NS_ :

BS_:

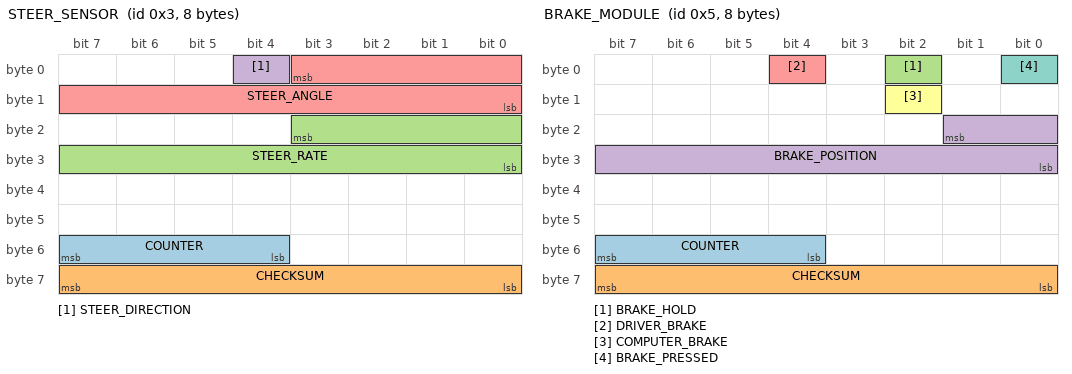
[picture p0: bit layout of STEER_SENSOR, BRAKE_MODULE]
BO_ 3 STEER_SENSOR: 8 XXX
 SG_ COUNTER : 55|4@0+ (1,0) [0|15] "" XXX
 SG_ CHECKSUM : 63|8@0+ (1,0) [0|255] "" XXX
 SG_ STEER_RATE : 19|12@0- (0.5,0) [0|255] "" XXX
 SG_ STEER_DIRECTION : 4|1@0+ (1,2) [0|1] "" XXX
 SG_ STEER_ANGLE : 3|12@0- (-0.5,0) [-500|500] "degrees" XXX

BO_ 5 BRAKE_MODULE: 8 XXX
 SG_ COUNTER : 55|4@0+ (1,0) [0|15] "" XXX
 SG_ CHECKSUM : 63|8@0+ (1,0) [0|255] "" XXX
 SG_ BRAKE_HOLD : 2|1@0+ (1,0) [0|1] "" XXX
 SG_ BRAKE_POSITION : 17|10@0+ (1,0) [0|65535] "" XXX
 SG_ DRIVER_BRAKE : 4|1@0+ (1,0) [0|1] "" XXX
 SG_ COMPUTER_BRAKE : 10|1@0+ (1,0) [0|1] "" XXX
 SG_ BRAKE_PRESSED : 0|1@1+ (1,0) [0|1] "" XXX

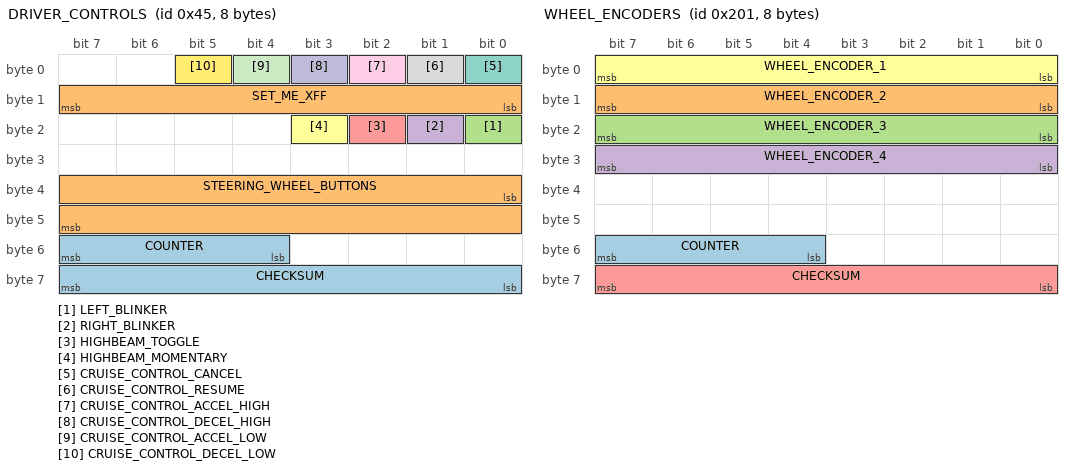
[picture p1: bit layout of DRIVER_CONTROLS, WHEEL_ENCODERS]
BO_ 69 DRIVER_CONTROLS: 8 XXX
 SG_ COUNTER : 55|4@0+ (1,0) [0|15] "" XXX
 SG_ STEERING_WHEEL_BUTTONS : 32|16@1+ (1,0) [0|255] "4 directional, 2 volume control & 2 phone buttons" XXX
 SG_ LEFT_BLINKER : 16|1@0+ (1,0) [0|1] "" XXX
 SG_ RIGHT_BLINKER : 17|1@0+ (1,0) [0|1] "" XXX
 SG_ HIGHBEAM_TOGGLE : 18|1@0+ (1,0) [0|1] "" XXX
 SG_ HIGHBEAM_MOMENTARY : 19|1@0+ (1,0) [0|1] "" XXX
 SG_ CRUISE_CONTROL_CANCEL : 0|1@0+ (1,0) [0|1] "" XXX
 SG_ CRUISE_CONTROL_RESUME : 1|1@0+ (1,0) [0|1] "" XXX
 SG_ CRUISE_CONTROL_ACCEL_HIGH : 2|1@0+ (1,0) [0|1] "" XXX
 SG_ CRUISE_CONTROL_DECEL_HIGH : 3|1@0+ (1,0) [0|1] "" XXX
 SG_ CRUISE_CONTROL_ACCEL_LOW : 4|1@0+ (1,0) [0|1] "" XXX
 SG_ CRUISE_CONTROL_DECEL_LOW : 5|1@0+ (1,0) [0|1] "" XXX
 SG_ CHECKSUM : 63|8@0+ (1,0) [0|255] "" XXX
 SG_ SET_ME_XFF : 15|8@0+ (1,0) [0|255] "" XXX

BO_ 513 WHEEL_ENCODERS: 8 XXX
 SG_ COUNTER : 55|4@0+ (1,0) [0|15] "" XXX
 SG_ WHEEL_ENCODER_2 : 15|8@0+ (1,0) [0|255] "" XXX
 SG_ WHEEL_ENCODER_3 : 23|8@0+ (1,0) [0|255] "" XXX
 SG_ WHEEL_ENCODER_4 : 31|8@0+ (1,0) [0|255] "" XXX
 SG_ CHECKSUM : 56|8@1+ (1,0) [0|255] "" XXX
 SG_ WHEEL_ENCODER_1 : 7|8@0+ (1,0) [0|255] "" XXX

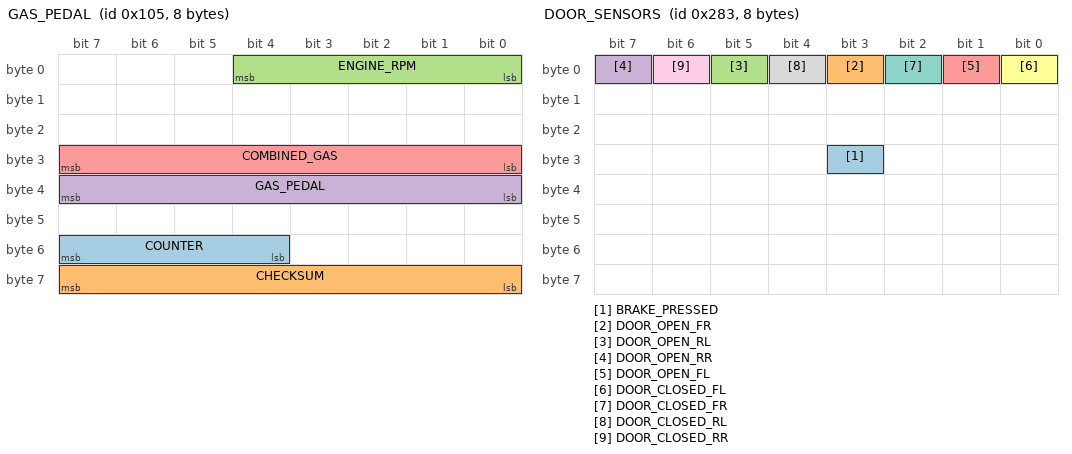
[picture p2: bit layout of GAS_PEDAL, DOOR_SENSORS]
BO_ 261 GAS_PEDAL: 8 XXX
 SG_ COUNTER : 55|4@0+ (1,0) [0|15] "" XXX
 SG_ CHECKSUM : 63|8@0+ (1,0) [0|255] "" XXX
 SG_ ENGINE_RPM : 4|5@0+ (1,0) [0|255] "" XXX
 SG_ GAS_PEDAL : 39|8@0+ (1,0) [0|255] "" XXX
 SG_ COMBINED_GAS : 31|8@0+ (1,0) [0|255] "" XXX

BO_ 643 DOOR_SENSORS: 8 XXX
 SG_ BRAKE_PRESSED : 27|1@0+ (1,0) [0|1] "" XXX
 SG_ DOOR_OPEN_FR : 3|1@1+ (1,0) [0|3] "" XXX
 SG_ DOOR_OPEN_RL : 5|1@0+ (1,0) [0|3] "" XXX
 SG_ DOOR_OPEN_RR : 7|1@0+ (1,0) [0|3] "" XXX
 SG_ DOOR_OPEN_FL : 1|1@0+ (1,0) [0|1] "" XXX
 SG_ DOOR_CLOSED_FL : 0|1@0+ (1,0) [0|1] "" XXX
 SG_ DOOR_CLOSED_FR : 2|1@0+ (1,0) [0|1] "" XXX
 SG_ DOOR_CLOSED_RL : 4|1@0+ (1,0) [0|1] "" XXX
 SG_ DOOR_CLOSED_RR : 6|1@0+ (1,0) [0|1] "" XXX

BO_ 885 SEATBELT_SENSORS: 8 XXX
 SG_ SEATBELT_DRIVER_LATCHED : 16|1@0+ (1,0) [0|1] "" XXX
 SG_ SEATBELT_PASSENGER_LATCHED : 18|1@0+ (1,0) [0|1] "" XXX

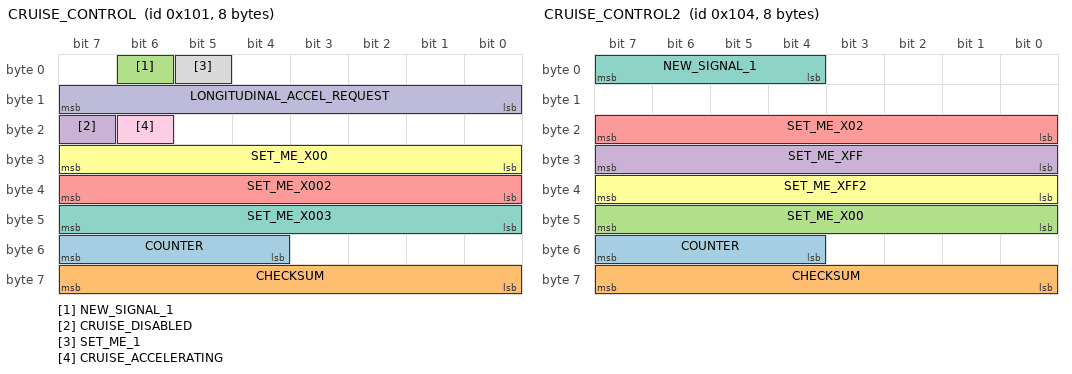
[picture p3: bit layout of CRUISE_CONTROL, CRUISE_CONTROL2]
BO_ 257 CRUISE_CONTROL: 8 XXX
 SG_ COUNTER : 55|4@0+ (1,0) [0|15] "" XXX
 SG_ CHECKSUM : 63|8@0+ (1,0) [0|255] "" XXX
 SG_ NEW_SIGNAL_1 : 6|1@0+ (1,0) [0|255] "" XXX
 SG_ CRUISE_DISABLED : 23|1@0+ (1,0) [0|1] "" XXX
 SG_ SET_ME_X002 : 39|8@0+ (1,0) [0|255] "" XXX
 SG_ SET_ME_X00 : 31|8@0+ (1,0) [0|255] "" XXX
 SG_ SET_ME_X003 : 47|8@0+ (1,0) [0|255] "" XXX
 SG_ SET_ME_1 : 5|1@0+ (1,0) [0|1] "" XXX
 SG_ CRUISE_ACCELERATING : 22|1@0+ (1,0) [0|1] "" XXX
 SG_ LONGITUDINAL_ACCEL_REQUEST : 15|8@0- (1,0) [0|127] "" XXX

BO_ 260 CRUISE_CONTROL2: 8 XXX
 SG_ COUNTER : 55|4@0+ (1,0) [0|15] "" XXX
 SG_ CHECKSUM : 63|8@0+ (1,0) [0|255] "" XXX
 SG_ SET_ME_X00 : 47|8@0+ (1,0) [0|255] "" XXX
 SG_ SET_ME_XFF : 31|8@0+ (1,0) [0|65535] "" XXX
 SG_ SET_ME_X02 : 23|8@0+ (1,0) [0|255] "" XXX
 SG_ SET_ME_XFF2 : 39|8@0+ (1,0) [0|255] "" XXX
 SG_ NEW_SIGNAL_1 : 7|4@0+ (1,0) [0|255] "" XXX

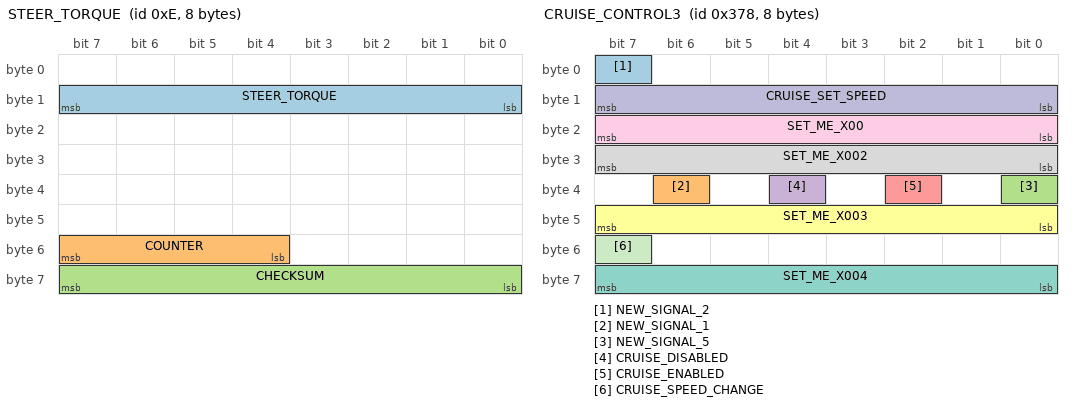
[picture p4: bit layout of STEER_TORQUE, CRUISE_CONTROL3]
BO_ 14 STEER_TORQUE: 8 XXX
 SG_ STEER_TORQUE : 15|8@0+ (1,0) [0|255] "" XXX
 SG_ COUNTER : 55|4@0+ (1,0) [0|15] "" XXX
 SG_ CHECKSUM : 63|8@0+ (1,0) [0|255] "" XXX

BO_ 888 CRUISE_CONTROL3: 8 XXX
 SG_ NEW_SIGNAL_2 : 7|1@0+ (1,0) [0|1] "" XXX
 SG_ NEW_SIGNAL_1 : 38|1@0+ (1,0) [0|1] "" XXX
 SG_ NEW_SIGNAL_5 : 32|1@0+ (1,0) [0|1] "" XXX
 SG_ CRUISE_DISABLED : 36|1@0+ (1,0) [0|1] "" XXX
 SG_ CRUISE_ENABLED : 34|1@0+ (1,0) [0|1] "" XXX
 SG_ SET_ME_X003 : 47|8@0+ (1,0) [0|255] "" XXX
 SG_ SET_ME_X004 : 63|8@0+ (1,0) [0|255] "" XXX
 SG_ SET_ME_X002 : 31|8@0+ (1,0) [0|255] "" XXX
 SG_ SET_ME_X00 : 23|8@0+ (1,0) [0|255] "" XXX
 SG_ CRUISE_SET_SPEED : 15|8@0+ (1,0) [0|63] "mph" XXX
 SG_ CRUISE_SPEED_CHANGE : 55|1@0+ (1,0) [0|1] "" XXX

BO_ 307 POWER_SEATS: 8 XXX
 SG_ DRIVER_FORWARD : 0|1@0+ (1,0) [0|1] "" XXX
 SG_ DRIVER_BACK : 1|1@0+ (1,0) [0|1] "" XXX

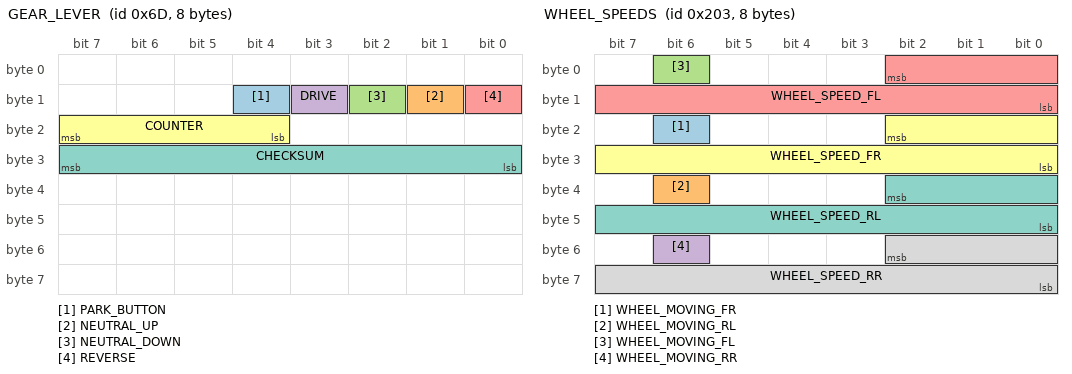
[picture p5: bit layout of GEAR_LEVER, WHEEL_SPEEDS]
BO_ 109 GEAR_LEVER: 8 XXX
 SG_ PARK_BUTTON : 12|1@0+ (1,0) [0|1] "" XXX
 SG_ NEUTRAL_UP : 9|1@0+ (1,0) [0|1] "" XXX
 SG_ NEUTRAL_DOWN : 10|1@0+ (1,0) [0|1] "" XXX
 SG_ DRIVE : 11|1@0+ (1,0) [0|1] "" XXX
 SG_ REVERSE : 8|1@0+ (1,0) [0|1] "" XXX
 SG_ COUNTER : 23|4@0+ (1,0) [0|15] "" XXX
 SG_ CHECKSUM : 31|8@0+ (1,0) [0|255] "" XXX

BO_ 115 GEAR_PACKET: 8 XXX
 SG_ GEAR : 0|4@1+ (1,0) [0|15] "" XXX

BO_ 581 IGNITION: 8 XXX

BO_ 515 WHEEL_SPEEDS: 8 XXX
 SG_ WHEEL_MOVING_FR : 22|1@1+ (1,0) [0|15] "" XXX
 SG_ WHEEL_MOVING_RL : 38|1@0+ (1,0) [0|1] "" XXX
 SG_ WHEEL_MOVING_FL : 6|1@0+ (1,0) [0|1] "" XXX
 SG_ WHEEL_MOVING_RR : 54|1@0+ (1,0) [0|1] "" XXX
 SG_ WHEEL_SPEED_FL : 2|11@0+ (0.0375,0) [0|255] "mph" XXX
 SG_ WHEEL_SPEED_FR : 18|11@0+ (0.0375,0) [0|255] "mph" XXX
 SG_ WHEEL_SPEED_RL : 34|11@0+ (0.0375,0) [0|255] "mph" XXX
 SG_ WHEEL_SPEED_RR : 50|11@0+ (0.0375,0) [0|255] "mph" XXX

BU_: RRSRR_FO LRSRR_FO CIPM_FO _DOFIMU2_FO _DOFIMU1_FO DMS_FO AMM_FO EOCM2B_IMX6_FO EOCM2B_K2_FO EOCM2B_K1_FO EOCM2A_IMX6_FO EOCM2A_K2_FO EOCM2A_K1_FO NVS_FO Dummy_FO TestTool_FO LRR_FO RFSRR_FO LFSRR_FO RSRR_FO VIS_FO EOCM_F_FO VIS2_FO
VAL_TABLE_ vt_BooleanValues 1 "true" 0 "false" ;
VAL_TABLE_ FrntVsnInPthVehBrkNwSt 10 "Active" 5 "Inactive" ;
VAL_TABLE_ FrntVsnClostPedBrkNwSt 10 "Active" 5 "Inactive" ;
VAL_TABLE_ DrvrMonSysEngSt 7 "Unused and Reserved 1" 6 "Recovering" 5 "Tracking" 4 "Searching" 3 "Video test port only" 2 "Idle" 1 "Invalid state" 0 "Does not exist or DME" ;
VAL_TABLE_ DrvrMonEngUnrecvrFltCod 7 "Unused and Reserved 3" 6 "Unused and Reserved 2" 5 "Unused and Reserved 1" 4 "Vehicle power supply Errors" 3 "Problem with LED illuminators" 2 "Vehicle input signals Errors" 1 "Problem with imager" 0 "Ok" ;
VAL_TABLE_ DrvrMonEngRecvrFltCod 3 "Engine is unable to find a face" 2 "Input Images too dark" 1 "Input images too bright" 0 "Ok" ;
VAL_TABLE_ DrvrMntrSysVTP 1 "Video test port active" 0 "Video test port inactive" ;
VAL_TABLE_ DrvrAttnStatCnfdc 3 "High" 2 "Medium" 1 "Low" 0 "Lowest" ;
VAL_TABLE_ DrvrAttnStat 7 "Invalid" 6 "Driver is exhibiting sleep" 5 "Driver is exhibiting microsleep" 4 "Attention is Center Console" 3 "Attention is Drivers Lap" 2 "Attention is Off Road" 1 "Attention is On Road" 0 "Unknown" ;
VAL_TABLE_ PPSMd 7 "GNSS and RTX and DR and MM" 6 "DR ONLY" 5 "GNSS and RTX and DR" 4 "GNSS and SBAS and DR" 3 "GNSS and DR" 2 "GNSS and  RTX" 1 "GNSS and SBAS" 0 "GNSS Standalone" ;
VAL_TABLE_ AdvDrvAstMpPrfShrtAcur 3 "Accuracy Is Unknown" 2 "Lowest Accuracy" 1 "Medium Accuracy" 0 "Highest Accuracy" ;
VAL_TABLE_ AdvDrAstMpStbRtOfWay 3 "Not Applicable" 2 "Unknown" 1 "Sub Path Has Right Of Way Over Path" 0 "Path Has Right Of Way Over Sub Path" ;
VAL_TABLE_ AdvDrAstMpStbPrtCalRut 3 "Not Applicable" 2 "Unknown" 1 "Path From This Point On Is Part Of Calculated Route" 0 "Path From This Point On Is Not Part Of Calculated Route" ;
VAL_TABLE_ AdvDrAstMpStbMsgTyp 7 "Unused and Reserved 2" 6 "Metadata" 5 "Profile Long" 4 "Profile Short" 3 "Stub" 2 "Segment" 1 "Position" 0 "Unused and Reserved 1" ;
VAL_TABLE_ AdvDrAstMpStbFmOfWay 15 "Not Applicable" 14 "Pedestrian Zone" 13 "Entrance To Or Exit To Service" 12 "Entrance To Or Exit Of A Car Park" 11 "Service Road Or Frontage Road" 10 "Slip Road per Ramp" 9 "Slip Road per Ramp On A Freeway Or Controlled Access Road" 8 "Parallel Road" 7 "Unused and Reserved 2" 6 "Unused and Reserved 1" 5 "Traffic Square per Special Traffic Figure" 4 "Roundabout Circle" 3 "Single Carriageway" 2 "Multiple Carriageway Or Multiply Digitized Road" 1 "Freeway Or Controlled Access Road That Is Not A Slip Road Or Ramp" 0 "Unknown" ;
VAL_TABLE_ AdvDrAstMpStbCmplxInsct 3 "Not Applicable" 2 "Unknown" 1 "Stub Is Part Of Complex Intersection" 0 "Stub Is Not Part Of Complex Intersection" ;
VAL_TABLE_ AdvDrAstMpSegTunl 3 "Not Applicable" 2 "Unknown" 1 "Segment Is Part Of Tunnel" 0 "Segment Is Not A Part Of Tunnel" ;
VAL_TABLE_ AdvDrAstMpSegPrtCalRut 3 "Not Applicable" 2 "Unknown" 1 "Segment Is Part Of Calculated Route" 0 "Segment Is Not Part Of Calculated Route" ;
VAL_TABLE_ AdvDrAstMpSegMsgTyp 7 "Unused and Reserved 2" 6 "Metadata" 5 "Profile Long" 4 "Profile Short" 3 "Stub" 2 "Segment" 1 "Position" 0 "Unused and Reserved 1" ;
VAL_TABLE_ AdvDrAstMpSegFrmOfWay 15 "Not Applicable" 14 "Pedestrian Zone" 13 "Entrance To Or Exit To Service" 12 "Entrance To Or Exit Of A Car Park" 11 "Service Road Or Frontage Road" 10 "Slip Road per Ramp" 9 "Slip Road per Ramp On A Freeway Or Controlled Access Road" 8 "Parallel Road" 7 "Unused and Reserved 2" 6 "Unused and Reserved 1" 5 "Traffic Square per Special Traffic Figure" 4 "Roundabout Circle" 3 "Single Carriageway" 2 "Multiple Carriageway Or Multiply Digitized Road" 1 "Freeway Or Controlled Access Road That Is Not A Slip Road or Ramp" 0 "Unknown" ;
VAL_TABLE_ AdvDrAstMpSegEffSdLmtTp 7 "Not Applicable" 6 "Explicit Snow" 5 "Explicit Rain" 4 "Explicit Time Of Day" 3 "Explicit By Day" 2 "Explicit By Night" 1 "Explicit On Traffic Sign" 0 "Implicit" ;
VAL_TABLE_ AdvDrAstMpSegDivdRd 3 "Not Applicable" 2 "Unknown" 1 "Segment Is Part Of Divided Road" 0 "Segment Is Not Part Of Divided Road" ;
VAL_TABLE_ AdvDrAstMpSegCmplxInsct 3 "Not Applicable" 2 "Unknown" 1 "Segment Is Part Of Complex Intersection" 0 "Segment Is Not Part Of Complex Intersection" ;
VAL_TABLE_ AdvDrAstMpSegBrdg 3 "Not Applicable" 2 "Unknown" 1 "Segment Is Part Of Bridge" 0 "Segment Not Part Of Bridge" ;
VAL_TABLE_ AdvDrAstMpSegBldUpAra 3 "Not Applicable" 2 "Unknown" 1 "Segment Is Part Of Built Up Area" 0 "Segment Is Not Part Of Built Up Area" ;
VAL_TABLE_ AdvDrAstMpMtdtSpdUnt 1 "Miles Per Hour" 0 "Kilometers Per Hour" ;
VAL_TABLE_ AdvDrAstMpMtdtDrvSd 1 "Driving Side Right" 0 "Driving Side Left" ;
VAL_TABLE_ WSMR_WiFiAssnReq 3 "Unexpected Undefined Connection Behavior" 2 "Wi Fi association failed with available credentials" 1 "Failed to receive Wi Fi credentials after 255 attempts" 0 "SSID and Passphrase Request" ;
VAL_TABLE_ StrgColCommsFlt 2 "Disabled Communications DTC" 1 "No Communications Fault" 0 "Communications Fault" ;
VAL_TABLE_ CPMAPINFO4 1 "Hardware Or Software Error" 0 "No Hardware Or Software Error" ;
VAL_TABLE_ AdvDrvAstMpPrfShrt2Acur 3 "Accuracy Is Unknown" 2 "Lowest Accuracy" 1 "Medium Accuracy" 0 "Highest Accuracy" ;
VAL_TABLE_ InterLghtStat 1 "Interior Lights On" 0 "Interior Light Off" ;
VAL_TABLE_ VehLnStatConf 2 "High Confidence" 1 "Low Confidence" 0 "No Confidence" 3 "Very High Confidence" ;
VAL_TABLE_ VehLnStat 3 "Lane Change To Right" 2 "Lane Change To Left" 1 "Staying in Lane" 0 "Unknown" ;
VAL_TABLE_ HrznPrvdRstRq 1 "Reset Not Required" 0 "Reset Required" ;
VAL_TABLE_ ExptNxtTrnstnDirConf 3 "Very High Confidence" 2 "High Confidence" 1 "Low Confidence" 0 "No Confidence" ;
VAL_TABLE_ ExptNxtTrnstnDir 7 "Reserved4" 6 "Reserved3" 5 "Reserved2" 4 "Reserved1" 3 "Traversing Middle Transition" 2 "Traversing Next Transition Right" 1 "Traversing Next Transition Left" 0 "Unknown" ;
VAL_TABLE_ ADASISMsgTypRetrans 7 "GM System Specific" 6 "Meta Data" 5 "Profile Long" 4 "Profile Short" 3 "Stub" 2 "Segment" 1 "Position" 0 "Checksum" ;
VAL_TABLE_ NVSysStat 7 "Needs Headlights" 6 "Temporarily Unavailable" 5 "Not Dark" 4 "Needs Service" 3 "Active" 2 "Inactive" 1 "Initializing" 0 "Unknown" ;
VAL_TABLE_ NVSysPedWrnIndReq 3 "Unused & Reserved" 2 "Pedestrian Alert" 1 "Pedestrian Detected" 0 "None" ;
VAL_TABLE_ NVSysPedDetCstReq 2 "On" 1 "Off" 0 "No Value" ;
VAL_TABLE_ NVSysPedDetCsCrStVal 2 "On" 1 "Off" 0 "No Value" ;
VAL_TABLE_ FwVsnCinCoutPotT9Rev 2 "Right" 1 "Left" 0 "None" ;
VAL_TABLE_ FwVsnCinCoutPotT8Rev 2 "Right" 1 "Left" 0 "None" ;
VAL_TABLE_ FwVsnCinCoutPotT7Rev 2 "Right" 1 "Left" 0 "None" ;
VAL_TABLE_ FwVsnCinCoutPotT6Rev 2 "Right" 1 "Left" 0 "None" ;
VAL_TABLE_ FwVsnCinCoutPotT5Rev 2 "Right" 1 "Left" 0 "None" ;
VAL_TABLE_ FwVsnCinCoutPotT4Rev 2 "Right" 1 "Left" 0 "None" ;
VAL_TABLE_ FwVsnCinCoutPotT3Rev 2 "Right" 1 "Left" 0 "None" ;
VAL_TABLE_ FwVsnCinCoutPotT2Rev 2 "Right" 1 "Left" 0 "None" ;
VAL_TABLE_ FwVsnCinCoutPotT1Rev 2 "Right" 1 "Left" 0 "None" ;
VAL_TABLE_ FwVsnCinCoutPotT12Rev 2 "Right" 1 "Left" 0 "None" ;
VAL_TABLE_ FwVsnCinCoutPotT11Rev 2 "Right" 1 "Left" 0 "None" ;
VAL_TABLE_ FwVsnCinCoutPotT10Rev 2 "Right" 1 "Left" 0 "None" ;
VAL_TABLE_ GFHBObjDirTrk8 1 "Ahead Traffic" 0 "Incoming Traffic" ;
VAL_TABLE_ GFHBObjDirTrk7 1 "Ahead Traffic" 0 "Incoming Traffic" ;
VAL_TABLE_ GFHBObjDirTrk6 1 "Ahead Traffic" 0 "Incoming Traffic" ;
VAL_TABLE_ GFHBObjDirTrk5 1 "Ahead Traffic" 0 "Incoming Traffic" ;
VAL_TABLE_ GFHBObjDirTrk4 1 "Ahead Traffic" 0 "Incoming Traffic" ;
VAL_TABLE_ GFHBObjDirTrk3 1 "Ahead Traffic" 0 "Incoming Traffic" ;
VAL_TABLE_ GFHBObjDirTrk2 1 "Ahead Traffic" 0 "Incoming Traffic" ;
VAL_TABLE_ GFHBObjDirTrk1 1 "Ahead Traffic" 0 "Incoming Traffic" ;
VAL_TABLE_ GFHBFwVsnRelLaneTrk8 3 "Left Lane" 2 "Right Lane" 1 "Host Lane" 0 "Unknown" ;
VAL_TABLE_ GFHBFwVsnRelLaneTrk7 3 "Left Lane" 2 "Right Lane" 1 "Host Lane" 0 "Unknown" ;
VAL_TABLE_ GFHBFwVsnRelLaneTrk6 3 "Left Lane" 2 "Right Lane" 1 "Host Lane" 0 "Unknown" ;
VAL_TABLE_ GFHBFwVsnRelLaneTrk5 3 "Left Lane" 2 "Right Lane" 1 "Host Lane" 0 "Unknown" ;
VAL_TABLE_ GFHBFwVsnRelLaneTrk4 3 "Left Lane" 2 "Right Lane" 1 "Host Lane" 0 "Unknown" ;
VAL_TABLE_ GFHBFwVsnRelLaneTrk3 3 "Left Lane" 2 "Right Lane" 1 "Host Lane" 0 "Unknown" ;
VAL_TABLE_ GFHBFwVsnRelLaneTrk2 3 "Left Lane" 2 "Right Lane" 1 "Host Lane" 0 "Unknown" ;
VAL_TABLE_ GFHBFwVsnRelLaneTrk1 3 "Left Lane" 2 "Right Lane" 1 "Host Lane" 0 "Unknown" ;
VAL_TABLE_ GFHBFwVsnMesStatTrk8 3 "Measured this cycle" 2 "Latent track not detected this cycle" 1 "New Object" 0 "No Object" ;
VAL_TABLE_ GFHBFwVsnMesStatTrk7 3 "Measured this cycle" 2 "Latent track not detected this cycle" 1 "New Object" 0 "No Object" ;
VAL_TABLE_ GFHBFwVsnMesStatTrk6 3 "Measured this cycle" 2 "Latent track not detected this cycle" 1 "New Object" 0 "No Object" ;
VAL_TABLE_ GFHBFwVsnMesStatTrk5 3 "Measured this cycle" 2 "Latent track not detected this cycle" 1 "New Object" 0 "No Object" ;
VAL_TABLE_ GFHBFwVsnMesStatTrk4 3 "Measured this cycle" 2 "Latent track not detected this cycle" 1 "New Object" 0 "No Object" ;
VAL_TABLE_ GFHBFwVsnMesStatTrk3 3 "Measured this cycle" 2 "Latent track not detected this cycle" 1 "New Object" 0 "No Object" ;
VAL_TABLE_ GFHBFwVsnMesStatTrk2 3 "Measured this cycle" 2 "Latent track not detected this cycle" 1 "New Object" 0 "No Object" ;
VAL_TABLE_ GFHBFwVsnMesStatTrk1 3 "Measured this cycle" 2 "Latent track not detected this cycle" 1 "New Object" 0 "No Object" ;
VAL_TABLE_ GFHBFwVsnCnfdncTrk8 3 "Confident" 2 "Speculative" 1 "Highly Speculative" 0 "Invalid" ;
VAL_TABLE_ GFHBFwVsnCnfdncTrk7 3 "Confident" 2 "Speculative" 1 "Highly Speculative" 0 "Invalid" ;
VAL_TABLE_ GFHBFwVsnCnfdncTrk6 3 "Confident" 2 "Speculative" 1 "Highly Speculative" 0 "Invalid" ;
VAL_TABLE_ GFHBFwVsnCnfdncTrk5 3 "Confident" 2 "Speculative" 1 "Highly Speculative" 0 "Invalid" ;
VAL_TABLE_ GFHBFwVsnCnfdncTrk4 3 "Confident" 2 "Speculative" 1 "Highly Speculative" 0 "Invalid" ;
VAL_TABLE_ GFHBFwVsnCnfdncTrk3 3 "Confident" 2 "Speculative" 1 "Highly Speculative" 0 "Invalid" ;
VAL_TABLE_ GFHBFwVsnCnfdncTrk2 3 "Confident" 2 "Speculative" 1 "Highly Speculative" 0 "Invalid" ;
VAL_TABLE_ GFHBFwVsnCnfdncTrk1 0 "Invalid" 3 "Confident" 2 "Speculative" 1 "Highly Speculative" ;
VAL_TABLE_ GFHBFVsnObjTypTrkRev8 12 "Cluster Object" 11 "Child Close to Danger Zone" 10 "Pedestrian Moving Out of Danger Zone" 9 "Pedestrian Moving Into Danger Zone" 8 "Pedestrian Standing Outside Danger Zone" 7 "No Object Present" 6 "Fixed Roadside Object" 5 "Fixed Overhead Object" 4 "Pedestrian" 3 "Motorcycle/ Bicycle" 2 "Large Vehicle (Semi)" 1 "4 Wheel Vehicle (Car)" 0 "Unknown" ;
VAL_TABLE_ GFHBFVsnObjTypTrkRev7 12 "Cluster Object" 11 "Child Close to Danger Zone" 10 "Pedestrian Moving Out of Danger Zone" 9 "Pedestrian Moving Into Danger Zone" 8 "Pedestrian Standing Outside Danger Zone" 7 "No Object Present" 6 "Fixed Roadside Object" 5 "Fixed Overhead Object" 4 "Pedestrian" 3 "Motorcycle/ Bicycle" 2 "Large Vehicle (Semi)" 1 "4 Wheel Vehicle (Car)" 0 "Unknown" ;
VAL_TABLE_ GFHBFVsnObjTypTrkRev6 12 "Cluster Object" 11 "Child Close to Danger Zone" 10 "Pedestrian Moving Out of Danger Zone" 9 "Pedestrian Moving Into Danger Zone" 8 "Pedestrian Standing Outside Danger Zone" 7 "No Object Present" 6 "Fixed Roadside Object" 5 "Fixed Overhead Object" 4 "Pedestrian" 3 "Motorcycle/ Bicycle" 2 "Large Vehicle (Semi)" 1 "4 Wheel Vehicle (Car)" 0 "Unknown" ;
VAL_TABLE_ GFHBFVsnObjTypTrkRev5 12 "Cluster Object" 11 "Child Close to Danger Zone" 10 "Pedestrian Moving Out of Danger Zone" 9 "Pedestrian Moving Into Danger Zone" 8 "Pedestrian Standing Outside Danger Zone" 7 "No Object Present" 6 "Fixed Roadside Object" 5 "Fixed Overhead Object" 4 "Pedestrian" 3 "Motorcycle/ Bicycle" 2 "Large Vehicle (Semi)" 1 "4 Wheel Vehicle (Car)" 0 "Unknown" ;
VAL_TABLE_ GFHBFVsnObjTypTrkRev4 12 "Cluster Object" 11 "Child Close to Danger Zone" 10 "Pedestrian Moving Out of Danger Zone" 9 "Pedestrian Moving Into Danger Zone" 8 "Pedestrian Standing Outside Danger Zone" 7 "No Object Present" 6 "Fixed Roadside Object" 5 "Fixed Overhead Object" 4 "Pedestrian" 3 "Motorcycle/ Bicycle" 2 "Large Vehicle (Semi)" 1 "4 Wheel Vehicle (Car)" 0 "Unknown" ;
VAL_TABLE_ GFHBFVsnObjTypTrkRev3 12 "Cluster Object" 11 "Child Close to Danger Zone" 10 "Pedestrian Moving Out of Danger Zone" 9 "Pedestrian Moving Into Danger Zone" 8 "Pedestrian Standing Outside Danger Zone" 7 "No Object Present" 6 "Fixed Roadside Object" 5 "Fixed Overhead Object" 4 "Pedestrian" 3 "Motorcycle/ Bicycle" 2 "Large Vehicle (Semi)" 1 "4 Wheel Vehicle (Car)" 0 "Unknown" ;
VAL_TABLE_ GFHBFVsnObjTypTrkRev2 12 "Cluster Object" 11 "Child Close to Danger Zone" 10 "Pedestrian Moving Out of Danger Zone" 9 "Pedestrian Moving Into Danger Zone" 8 "Pedestrian Standing Outside Danger Zone" 7 "No Object Present" 6 "Fixed Roadside Object" 5 "Fixed Overhead Object" 4 "Pedestrian" 3 "Motorcycle/ Bicycle" 2 "Large Vehicle (Semi)" 1 "4 Wheel Vehicle (Car)" 0 "Unknown" ;
VAL_TABLE_ GFHBFVsnObjTypTrkRev1 12 "Cluster Object" 11 "Child Close to Danger Zone" 10 "Pedestrian Moving Out of Danger Zone" 9 "Pedestrian Moving Into Danger Zone" 8 "Pedestrian Standing Outside Danger Zone" 7 "No Object Present" 6 "Fixed Roadside Object" 5 "Fixed Overhead Object" 4 "Pedestrian" 3 "Motorcycle/ Bicycle" 2 "Large Vehicle (Semi)" 1 "4 Wheel Vehicle (Car" 0 "Unknown" ;
VAL_TABLE_ CRL_Cnfdnc 7 "Reserved4" 6 "Reserved3" 5 "Reserved2" 4 "Reserved1" 3 "Best" 2 "Marking Present" 1 "Weak Marking" 0 "No Lane" ;
VAL_TABLE_ CLL_Cnfdnc 7 "Reserved4" 6 "Reserved3" 5 "Reserved2" 4 "Reserved1" 3 "Best" 2 "Marking Present" 1 "Weak Marking" 0 "No Lane" ;
VAL_TABLE_ VBBrkCtrlSt 4 "Release Control" 3 "Hold Vehicle" 2 "Apply Brake" 1 "Decrease Torque" 0 "No Action" ;
VAL_TABLE_ ObstacleType 6 "NO_OBJECT" 5 "OBJ_GUARDRAIL" 4 "OBJ_TUNNEL " 3 "OBJ_TRAFFIC_SIGN" 2 "OBJ_VEHICLE" 1 "OBJ_BRIDGE " 0 "OBJ_UNKNOWN" ;
VAL_TABLE_ VpathMode 2 "Mid Hi Speed" 1 "Low Speed" 0 "Disabled" ;
VAL_TABLE_ LaneChngStatus 2 "Lane Change Right" 1 "Lane Change Left" 0 "Idle" ;
VAL_TABLE_ TravelDirection 3 "Other (excessive side slip)" 2 "reverse / stopped in rvrs gear" 1 "Forward / stopped in frwd gear" 0 "Unknown" ;
VAL_TABLE_ TrueOrFalse 1 "true" 0 "false" ;
VAL_TABLE_ ModeCommand 5 "Sensing with Reduced Power" 4 "Undefined" 3 "Radio Silent" 2 "Sensing" 1 "Not Sensing" 0 "Undefined" ;
VAL_TABLE_ LaneSnsLLnPosValid 1 "Invalid" 0 "Valid" ;
VAL_TABLE_ LnSnsRLnPosValid 1 "Invalid" 0 "Valid" ;
VAL_TABLE_ Elevation 3 "Low " 2 "mid (reserved)" 1 "high " 0 "Unknown" ;
VAL_TABLE_ ModeCommandFdbk 5 "Sensing with reduced power" 4 "Undefined" 3 "Radio Silent" 2 "Sensing" 1 "Not Sensing" 0 "Undefined" ;
VAL_TABLE_ relativeLane 3 "Left Lane" 2 "Right Lane" 1 "Host Lane" 0 "Unknown" ;
VAL_TABLE_ RoadTypeInfo 5 "Constiction Zone Exit" 4 "Construction Zone Entry" 3 "Highway" 2 "Secondary Road" 1 "City" 0 "Unknown" ;
VAL_TABLE_ ObjectLossInfo 2 "elevation conditions" 1 "tight curve" 0 "not lost" ;
VAL_TABLE_ MeasurementStatus 3 "Measured this cycle" 2 "Latent track not detctd this cyc" 1 "New Object" 0 "No Object" ;
VAL_TABLE_ ObjectType 7 "no object present" 6 "fixed roadside object" 5 "fixed overhead object" 4 "pedestrian" 3 "motocycle  / bicycle" 2 "Large vehicle (semi)" 1 "4 Wheel Vehicle (car, small trk)" 0 "Unknown" ;
VAL_TABLE_ Confidence 3 "confident" 2 "speculative" 1 "highly speculative" 0 "invalid" ;
VAL_TABLE_ DynamicProp 4 "Moving in opposite direction" 3 "Moving in same direction as host" 2 "Has moved but currently stopped" 1 "Has never moved" 0 "Unknown" ;
VAL_TABLE_ DrvWndPosSt 6 "Fully Opened" 5 "Open More Than C" 4 "Position C" 3 "Position B" 2 "Position A" 1 "Open Less Than A" 0 "Fully Closed" ;
VAL_TABLE_ VehMovSta 4 "Invalid" 3 "Reverse" 2 "Forward" 1 "Neutral" 0 "Parked" ;
VAL_TABLE_ OtsdAmbtLtLvlStat 2 "Day" 1 "Night" 0 "Unknown" ;
VAL_TABLE_ RtTrnLmpAtv 2 "On with telltale" 1 "On without telltale" 0 "Off" ;
VAL_TABLE_ LftTrnLmpAtv 2 "On with telltale" 1 "On without telltale" 0 "Off" ;
VAL_TABLE_ HdlmpBmSelectStat 2 "High Beams" 1 "Low Beams" 0 "Unknown" ;
VAL_TABLE_ DTCI_DTCFaultType 3 "Type C" 2 "Type B" 1 "Type A" 0 "Not Supported" ;
VAL_TABLE_ TrnsShftLvrPos 13 "Forward Range J" 12 "Forward Range I" 15 "Lever Position Unknown" 11 "Forward Range H" 10 "Forward Range G" 9 "Forward Range F" 8 "Forward Range E" 7 "Forward Range D" 6 "Forward Range C" 5 "Forward Range B" 4 "Forward Range A" 3 "Neutral Range" 2 "Reverse Range" 1 "Park Range" 0 "Between Ranges" ;
VAL_TABLE_ SysPwrMd 3 "Crank Request" 2 "Run" 1 "Accessory" 0 "Off" ;
VAL_TABLE_ ValidityStates 1 "Invalid" 0 "Valid" ;

CM_ SG_ 1104 DRIVER_SEAT_BELT_ONOFF "0 - on , 1 = off";
CM_ SG_ 1056 DOOR_RL_STATUS "04 - RL - open";
CM_ SG_ 1056 DOOR_FL_STATUS "28 - FL open , 38 - FR";
CM_ SG_ 1056 RIGHT_SIGNAL_STATUS "R,L shows at same time means hazard";
CM_ SG_ 832 TRANS_MODE "AT - 85 / MT - 8D";
CM_ SG_ 832 TRANS_GEAR_POS "R-7 , 0 - N";
CM_ SG_ 821 CRUSE_ONOFF "Cruse Switch";
CM_ SG_ 821 CRUSE_ENABLED "Cruse enabled";
CM_ SG_ 821 THROTTLE_PEDAL_POS "Real Pedal Pos";
CM_ SG_ 821 THROTTLE_POS "Throttle Pos for Cruse Mode";
CM_ SG_ 906 ABS_UNDEF1 "ABS force";
CM_ SG_ 906 SPEED_FL "used for car speed in dash board";
VAL_ 481 DistanceButton 1 "Active" 0 "Inactive" ;
VAL_ 481 LKAButton 1 "Active" 0 "Inactive" ;
VAL_ 481 ACCButtons 6 "Cancel" 5 "Main" 3 "Set" 2 "Resume" 1 "None" ;
VAL_ 309 PRNDL 3 "Reverse" 2 "Drive" 1 "Neutral" 0 "Park" ;
VAL_ 338 LKASteeringCmdActive 1 "Active" 0 "Inactive" ;
VAL_ 338 LKASMode 2 "supercruise" 1 "lkas" 0 "Inactive" ;
VAL_ 880 ACCLeadCar 1 "Present" 0 "Not Present" ;
VAL_ 880 ACCGapLevel 3 "Far" 2 "Med" 1 "Near" 0 "Inactive" ;
VAL_ 880 ACCResumeButton 1 "Pressed" 0 "Depressed" ;
VAL_ 880 ACCCmdActive 1 "Active" 0 "Inactive" ;
VAL_ 356 LKATorqueDeliveredStatus 7 "Override Fault" 6 "LKAS Fault but Responsive" 5 "TBD but Responsive" 4 "TBD but Responsive" 3 "Fault" 1 "Active" 0 "Inactive" ;
VAL_ 489 BrakePedalPressed 1 "Pressed" 0 "Depressed" ;
VAL_ 715 GasRegenCmdActiveInv 1 "Inactive" 0 "Active" ;
